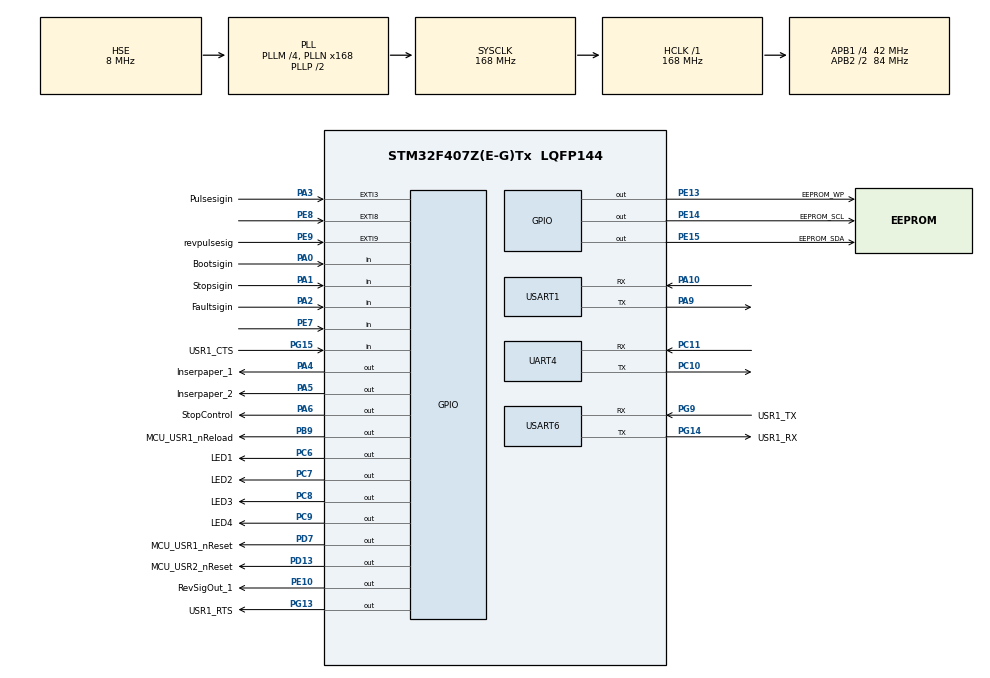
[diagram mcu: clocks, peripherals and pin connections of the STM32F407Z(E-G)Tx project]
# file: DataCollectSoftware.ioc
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Dma.Request0=USART6_TX
Dma.Request1=UART4_TX
Dma.Request2=UART4_RX
Dma.Request3=USART6_RX
Dma.Request4=USART1_RX
Dma.Request5=USART1_TX
Dma.UART4_RX.2.Direction=DMA_PERIPH_TO_MEMORY
Dma.UART4_RX.2.FIFOMode=DMA_FIFOMODE_DISABLE
Dma.UART4_RX.2.Instance=DMA1_Stream2
Dma.UART4_RX.2.MemDataAlignment=DMA_MDATAALIGN_BYTE
Dma.UART4_RX.2.MemInc=DMA_MINC_ENABLE
Dma.UART4_RX.2.Mode=DMA_NORMAL
Dma.UART4_RX.2.PeriphDataAlignment=DMA_PDATAALIGN_BYTE
Dma.UART4_RX.2.PeriphInc=DMA_PINC_DISABLE
Dma.UART4_RX.2.Priority=DMA_PRIORITY_LOW
Dma.UART4_TX.1.Direction=DMA_MEMORY_TO_PERIPH
Dma.UART4_TX.1.FIFOMode=DMA_FIFOMODE_DISABLE
Dma.UART4_TX.1.Instance=DMA1_Stream4
Dma.UART4_TX.1.MemDataAlignment=DMA_MDATAALIGN_BYTE
Dma.UART4_TX.1.MemInc=DMA_MINC_ENABLE
Dma.UART4_TX.1.Mode=DMA_NORMAL
Dma.UART4_TX.1.PeriphDataAlignment=DMA_PDATAALIGN_BYTE
Dma.UART4_TX.1.PeriphInc=DMA_PINC_DISABLE
Dma.UART4_TX.1.Priority=DMA_PRIORITY_LOW
Dma.USART1_RX.4.Direction=DMA_PERIPH_TO_MEMORY
Dma.USART1_RX.4.FIFOMode=DMA_FIFOMODE_DISABLE
Dma.USART1_RX.4.Instance=DMA2_Stream2
Dma.USART1_RX.4.MemDataAlignment=DMA_MDATAALIGN_BYTE
Dma.USART1_RX.4.MemInc=DMA_MINC_ENABLE
Dma.USART1_RX.4.Mode=DMA_NORMAL
Dma.USART1_RX.4.PeriphDataAlignment=DMA_PDATAALIGN_BYTE
Dma.USART1_RX.4.PeriphInc=DMA_PINC_DISABLE
Dma.USART1_RX.4.Priority=DMA_PRIORITY_LOW
Dma.USART1_TX.5.Direction=DMA_MEMORY_TO_PERIPH
Dma.USART1_TX.5.FIFOMode=DMA_FIFOMODE_DISABLE
Dma.USART1_TX.5.Instance=DMA2_Stream7
Dma.USART1_TX.5.MemDataAlignment=DMA_MDATAALIGN_BYTE
Dma.USART1_TX.5.MemInc=DMA_MINC_ENABLE
Dma.USART1_TX.5.Mode=DMA_NORMAL
Dma.USART1_TX.5.PeriphDataAlignment=DMA_PDATAALIGN_BYTE
Dma.USART1_TX.5.PeriphInc=DMA_PINC_DISABLE
Dma.USART1_TX.5.Priority=DMA_PRIORITY_LOW
Dma.USART6_RX.3.Direction=DMA_PERIPH_TO_MEMORY
Dma.USART6_RX.3.FIFOMode=DMA_FIFOMODE_DISABLE
Dma.USART6_RX.3.Instance=DMA2_Stream1
Dma.USART6_RX.3.MemDataAlignment=DMA_MDATAALIGN_BYTE
Dma.USART6_RX.3.MemInc=DMA_MINC_ENABLE
Dma.USART6_RX.3.Mode=DMA_NORMAL
Dma.USART6_RX.3.PeriphDataAlignment=DMA_PDATAALIGN_BYTE
Dma.USART6_RX.3.PeriphInc=DMA_PINC_DISABLE
Dma.USART6_RX.3.Priority=DMA_PRIORITY_LOW
Dma.USART6_TX.0.Direction=DMA_MEMORY_TO_PERIPH
Dma.USART6_TX.0.FIFOMode=DMA_FIFOMODE_DISABLE
Dma.USART6_TX.0.Instance=DMA2_Stream6
Dma.USART6_TX.0.MemDataAlignment=DMA_MDATAALIGN_BYTE
Dma.USART6_TX.0.MemInc=DMA_MINC_ENABLE
Dma.USART6_TX.0.Mode=DMA_NORMAL
Dma.USART6_TX.0.PeriphDataAlignment=DMA_PDATAALIGN_BYTE
Dma.USART6_TX.0.PeriphInc=DMA_PINC_DISABLE
Dma.USART6_TX.0.Priority=DMA_PRIORITY_LOW
FREERTOS.Mutexes01=CommitMutex,Dynamic,NULL
FREERTOS.Tasks01=Collect_Task,0,500,StartCollectTask,Default,NULL,Dynamic,NULL,NULL;Config_Task,-3,500,StartConfigTask,Default,NULL,Dynamic,NULL,NULL;OutControl_Task,-3,128,StartOutControlTask,Default,NULL,Dynamic,NULL,NULL
Mcu.Family=STM32F4
Mcu.Name=STM32F407Z(E-G)Tx
Mcu.Package=LQFP144
NVIC.DMA1_Stream2_IRQn=true\:5\:0\:false\:false\:true\:true\:false\:true
NVIC.DMA1_Stream4_IRQn=true\:5\:0\:false\:false\:true\:true\:false\:true
NVIC.DMA2_Stream1_IRQn=true\:5\:0\:false\:false\:true\:true\:false\:true
NVIC.DMA2_Stream2_IRQn=true\:5\:0\:false\:false\:true\:true\:false\:true
NVIC.DMA2_Stream6_IRQn=true\:5\:0\:false\:false\:true\:true\:true\:false
NVIC.DMA2_Stream7_IRQn=true\:5\:0\:false\:false\:true\:true\:false\:true
NVIC.EXTI3_IRQn=true\:5\:0\:true\:false\:true\:true\:true\:true
NVIC.EXTI9_5_IRQn=true\:5\:0\:false\:false\:true\:true\:true\:true
NVIC.PriorityGroup=NVIC_PRIORITYGROUP_4
NVIC.TIM2_IRQn=true\:5\:0\:false\:false\:true\:true\:true\:true
NVIC.TIM3_IRQn=true\:5\:0\:false\:false\:true\:true\:true\:true
NVIC.TIM4_IRQn=true\:5\:0\:false\:false\:true\:true\:true\:true
NVIC.TIM8_TRG_COM_TIM14_IRQn=true\:0\:0\:false\:false\:true\:false\:false\:false
NVIC.TimeBase=TIM8_TRG_COM_TIM14_IRQn
NVIC.TimeBaseIP=TIM14
NVIC.UART4_IRQn=true\:5\:0\:false\:false\:true\:true\:true\:true
NVIC.USART1_IRQn=true\:5\:0\:false\:false\:true\:true\:true\:true
NVIC.USART6_IRQn=true\:5\:0\:false\:false\:true\:true\:true\:true
PA0-WKUP.GPIO_Label=Bootsigin
PA0-WKUP.GPIO_Mode=GPIO_MODE_INPUT
PA0-WKUP.GPIO_PuPd=GPIO_NOPULL
PA0-WKUP.Signal=GPIO_Input
PA1.GPIO_Label=Stopsigin
PA1.GPIO_Mode=GPIO_MODE_INPUT
PA1.GPIO_PuPd=GPIO_NOPULL
PA1.Signal=GPIO_Input
PA10.Mode=Asynchronous
PA10.Signal=USART1_RX
PA13.Mode=JTAG_5_pins
PA13.Signal=SYS_JTMS-SWDIO
PA14.Mode=JTAG_5_pins
PA14.Signal=SYS_JTCK-SWCLK
PA15.Mode=JTAG_5_pins
PA15.Signal=SYS_JTDI
PA2.GPIO_Label=Faultsigin
PA2.GPIO_Mode=GPIO_MODE_INPUT
PA2.GPIO_PuPd=GPIO_NOPULL
PA2.Signal=GPIO_Input
PA3.GPIO_Label=Pulsesigin
PA3.GPIO_ModeDefaultEXTI=GPIO_MODE_IT_RISING_FALLING
PA3.Signal=GPXTI3
PA4.GPIO_Label=Inserpaper_1
PA4.GPIO_ModeDefaultOutputPP=GPIO_MODE_OUTPUT_PP
PA4.GPIO_PuPd=GPIO_PULLUP
PA4.GPIO_Speed=GPIO_SPEED_FREQ_LOW
PA4.PinState=GPIO_PIN_RESET
PA4.Signal=GPIO_Output
PA5.GPIO_Label=Inserpaper_2
PA5.GPIO_ModeDefaultOutputPP=GPIO_MODE_OUTPUT_PP
PA5.GPIO_PuPd=GPIO_PULLUP
PA5.GPIO_Speed=GPIO_SPEED_FREQ_LOW
PA5.PinState=GPIO_PIN_RESET
PA5.Signal=GPIO_Output
PA6.GPIO_Label=StopControl
PA6.GPIO_ModeDefaultOutputPP=GPIO_MODE_OUTPUT_PP
PA6.GPIO_PuPd=GPIO_PULLUP
PA6.GPIO_Speed=GPIO_SPEED_FREQ_LOW
PA6.PinState=GPIO_PIN_RESET
PA6.Signal=GPIO_Output
PA9.Mode=Asynchronous
PA9.Signal=USART1_TX
PB3.Mode=JTAG_5_pins
PB3.Signal=SYS_JTDO-SWO
PB4.Mode=JTAG_5_pins
PB4.Signal=SYS_JTRST
PB9.GPIO_Label=MCU_USR1_nReload
PB9.GPIO_ModeDefaultOutputPP=GPIO_MODE_OUTPUT_PP
PB9.GPIO_PuPd=GPIO_PULLUP
PB9.GPIO_Speed=GPIO_SPEED_FREQ_LOW
PB9.PinState=GPIO_PIN_SET
PB9.Signal=GPIO_Output
PC10.Mode=Asynchronous
PC10.Signal=UART4_TX
PC11.Mode=Asynchronous
PC11.Signal=UART4_RX
PC14-OSC32_IN.Mode=LSE-External-Oscillator
PC14-OSC32_IN.Signal=RCC_OSC32_IN
PC15-OSC32_OUT.Mode=LSE-External-Oscillator
PC15-OSC32_OUT.Signal=RCC_OSC32_OUT
PC6.GPIO_Label=LED1
PC6.GPIO_PuPd=GPIO_PULLUP
PC6.Signal=GPIO_Output
PC7.GPIO_Label=LED2
PC7.Signal=GPIO_Output
PC8.GPIO_Label=LED3
PC8.Signal=GPIO_Output
PC9.GPIO_Label=LED4
PC9.Signal=GPIO_Output
PD13.GPIO_Label=MCU_USR2_nReset
PD13.GPIO_PuPd=GPIO_PULLUP
PD13.Signal=GPIO_Output
PD7.GPIO_Label=MCU_USR1_nReset
PD7.GPIO_ModeDefaultOutputPP=GPIO_MODE_OUTPUT_PP
PD7.GPIO_PuPd=GPIO_PULLUP
PD7.GPIO_Speed=GPIO_SPEED_FREQ_LOW
PD7.PinState=GPIO_PIN_SET
PD7.Signal=GPIO_Output
PE10.GPIO_Label=RevSigOut_1
PE10.GPIO_ModeDefaultOutputPP=GPIO_MODE_OUTPUT_PP
PE10.GPIO_PuPd=GPIO_PULLUP
PE10.GPIO_Speed=GPIO_SPEED_FREQ_LOW
PE10.PinState=GPIO_PIN_RESET
PE10.Signal=GPIO_Output
PE13.GPIO_Label=EEPROM_WP
PE13.GPIO_ModeDefaultOutputPP=GPIO_MODE_OUTPUT_PP
PE13.GPIO_PuPd=GPIO_PULLUP
PE13.GPIO_Speed=GPIO_SPEED_FREQ_LOW
PE13.PinState=GPIO_PIN_RESET
PE13.Signal=GPIO_Output
PE14.GPIO_Label=EEPROM_SCL
PE14.GPIO_ModeDefaultOutputPP=GPIO_MODE_OUTPUT_PP
PE14.GPIO_PuPd=GPIO_PULLUP
PE14.GPIO_Speed=GPIO_SPEED_FREQ_HIGH
PE14.Signal=GPIO_Output
PE15.GPIO_Label=EEPROM_SDA
PE15.GPIO_ModeDefaultOutputPP=GPIO_MODE_OUTPUT_OD
PE15.GPIO_PuPd=GPIO_PULLUP
PE15.GPIO_Speed=GPIO_SPEED_FREQ_HIGH
PE15.Signal=GPIO_Output
PE7.Signal=GPIO_Input
PE8.GPIO_ModeDefaultEXTI=GPIO_MODE_IT_RISING_FALLING
PE8.Signal=GPXTI8
PE9.GPIO_Label=revpulsesig
PE9.GPIO_ModeDefaultEXTI=GPIO_MODE_IT_RISING_FALLING
PE9.Signal=GPXTI9
PG13.GPIO_Label=USR1_RTS
PG13.GPIO_ModeDefaultOutputPP=GPIO_MODE_OUTPUT_PP
PG13.GPIO_PuPd=GPIO_PULLUP
PG13.GPIO_Speed=GPIO_SPEED_FREQ_LOW
PG13.PinState=GPIO_PIN_RESET
PG13.Signal=GPIO_Output
PG14.GPIO_Label=USR1_RX
PG14.Mode=Asynchronous
PG14.Signal=USART6_TX
PG15.GPIO_Label=USR1_CTS
PG15.GPIO_Mode=GPIO_MODE_INPUT
PG15.GPIO_PuPd=GPIO_PULLUP
PG15.Signal=GPIO_Input
PG9.GPIO_Label=USR1_TX
PG9.Mode=Asynchronous
PG9.Signal=USART6_RX
PH0-OSC_IN.Mode=HSE-External-Oscillator
PH0-OSC_IN.Signal=RCC_OSC_IN
PH1-OSC_OUT.Mode=HSE-External-Oscillator
PH1-OSC_OUT.Signal=RCC_OSC_OUT
ProjectManager.HeapSize=0xc00
ProjectManager.StackSize=0x400
ProjectManager.TargetToolchain=MDK-ARM V5
RCC.48MHZClocksFreq_Value=84000000
RCC.AHBFreq_Value=168000000
RCC.APB1CLKDivider=RCC_HCLK_DIV4
RCC.APB1Freq_Value=42000000
RCC.APB1TimFreq_Value=84000000
RCC.APB2CLKDivider=RCC_HCLK_DIV2
RCC.APB2Freq_Value=84000000
RCC.APB2TimFreq_Value=168000000
RCC.CortexFreq_Value=168000000
RCC.HCLKFreq_Value=168000000
RCC.HSE_VALUE=8000000
RCC.HSI_VALUE=16000000
RCC.PLLM=4
RCC.PLLN=168
RCC.PLLSourceVirtual=RCC_PLLSOURCE_HSE
RCC.RCC_RTC_Clock_SourceVirtual=RCC_RTCCLKSOURCE_LSE
RCC.RCC_RTC_Clock_Source_FROM_HSE=RCC_RTCCLKSOURCE_HSE_DIV8
RCC.SYSCLKFreq_VALUE=168000000
RCC.SYSCLKSource=RCC_SYSCLKSOURCE_PLLCLK
RCC.VCOOutputFreq_Value=336000000
TIM2.AutoReloadPreload=TIM_AUTORELOAD_PRELOAD_ENABLE
TIM2.Period=1000
TIM2.Prescaler=83
TIM3.AutoReloadPreload=TIM_AUTORELOAD_PRELOAD_ENABLE
TIM3.Period=9999
TIM3.Prescaler=8399
TIM4.AutoReloadPreload=TIM_AUTORELOAD_PRELOAD_ENABLE
TIM4.Period=1000
TIM4.Prescaler=83
UART4.VirtualMode=Asynchronous
USART1.VirtualMode=VM_ASYNC
USART6.VirtualMode=VM_ASYNC
VP_FREERTOS_VS_CMSIS_V1.Mode=CMSIS_V1
VP_RTC_VS_RTC_Activate.Mode=RTC_Enabled
VP_SYS_VS_tim14.Mode=TIM14
VP_TIM2_VS_ClockSourceINT.Mode=Internal
VP_TIM3_VS_ClockSourceINT.Mode=Internal
VP_TIM4_VS_ClockSourceINT.Mode=Internal
board=custom

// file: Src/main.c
/* USER CODE BEGIN Header */
/**
  ******************************************************************************
  * @file           : main.c
  * @brief          : Main program body
  ******************************************************************************
  * This notice applies to any and all portions of this file
  * that are not between comment pairs USER CODE BEGIN and
  * USER CODE END. Other portions of this file, whether
  * inserted by the user or by software development tools
  * are owned by their respective copyright owners.
  *
  * Copyright (c) 2019 STMicroelectronics International N.V.
  * All rights reserved.
  *
  * Redistribution and use in source and binary forms, with or without
  * modification, are permitted, provided that the following conditions are met:
  *
  * 1. Redistribution of source code must retain the above copyright notice,
  *    this list of conditions and the following disclaimer.
  * 2. Redistributions in binary form must reproduce the above copyright notice,
  *    this list of conditions and the following disclaimer in the documentation
  *    and/or other materials provided with the distribution.
  * 3. Neither the name of STMicroelectronics nor the names of other
  *    contributors to this software may be used to endorse or promote products
  *    derived from this software without specific written permission.
  * 4. This software, including modifications and/or derivative works of this
  *    software, must execute solely and exclusively on microcontroller or
  *    microprocessor devices manufactured by or for STMicroelectronics.
  * 5. Redistribution and use of this software other than as permitted under
  *    this license is void and will automatically terminate your rights under
  *    this license.
  *
  * THIS SOFTWARE IS PROVIDED BY STMICROELECTRONICS AND CONTRIBUTORS "AS IS"
  * AND ANY EXPRESS, IMPLIED OR STATUTORY WARRANTIES, INCLUDING, BUT NOT
  * LIMITED TO, THE IMPLIED WARRANTIES OF MERCHANTABILITY, FITNESS FOR A
  * PARTICULAR PURPOSE AND NON-INFRINGEMENT OF THIRD PARTY INTELLECTUAL PROPERTY
  * RIGHTS ARE DISCLAIMED TO THE FULLEST EXTENT PERMITTED BY LAW. IN NO EVENT
  * SHALL STMICROELECTRONICS OR CONTRIBUTORS BE LIABLE FOR ANY DIRECT, INDIRECT,
  * INCIDENTAL, SPECIAL, EXEMPLARY, OR CONSEQUENTIAL DAMAGES (INCLUDING, BUT NOT
  * LIMITED TO, PROCUREMENT OF SUBSTITUTE GOODS OR SERVICES; LOSS OF USE, DATA,
  * OR PROFITS; OR BUSINESS INTERRUPTION) HOWEVER CAUSED AND ON ANY THEORY OF
  * LIABILITY, WHETHER IN CONTRACT, STRICT LIABILITY, OR TORT (INCLUDING
  * NEGLIGENCE OR OTHERWISE) ARISING IN ANY WAY OUT OF THE USE OF THIS SOFTWARE,
  * EVEN IF ADVISED OF THE POSSIBILITY OF SUCH DAMAGE.
  *
  ******************************************************************************
  */
/* USER CODE END Header */

#include "main.h"
#include "cmsis_os.h"
#include <stdio.h>

/* USER CODE BEGIN Includes */
#include "system_config.h"
#include "maincounter.h"
#include "qulitycounter.h"
#include "diechangecounter.h"

//#include "waveformcapture.h"

/* USER CODE END Includes */

/* USER CODE BEGIN PTD */
#define   APPLICATION_ADDR  0x08010000
/* USER CODE END PTD */

RTC_HandleTypeDef hrtc;

TIM_HandleTypeDef htim2;
TIM_HandleTypeDef htim3;
TIM_HandleTypeDef htim4;

UART_HandleTypeDef huart4;
UART_HandleTypeDef huart1;
UART_HandleTypeDef huart6;
DMA_HandleTypeDef hdma_uart4_tx;
DMA_HandleTypeDef hdma_uart4_rx;
DMA_HandleTypeDef hdma_usart1_rx;
DMA_HandleTypeDef hdma_usart1_tx;
DMA_HandleTypeDef hdma_usart6_tx;
DMA_HandleTypeDef hdma_usart6_rx;

osThreadId Collect_TaskHandle;
osThreadId Config_TaskHandle;
osThreadId OutControl_TaskHandle;
osThreadId Collect_TaskHandle_new;
osMutexId CommitMutexHandle;
/* USER CODE BEGIN PV */
SysCfg g_sys_cfg;
SysSts g_sys_sts;
/* USER CODE END PV */

void SystemClock_Config(void);
static void MX_GPIO_Init(void);
static void MX_DMA_Init(void);
static void MX_UART4_Init(void);
static void MX_USART6_UART_Init(void);
static void MX_RTC_Init(void);
static void MX_TIM2_Init(void);
static void MX_TIM3_Init(void);
static void MX_TIM4_Init(void);
static void MX_USART1_UART_Init(void);
void StartCollectTask(void const * argument);
void StartConfigTask(void const * argument);
void StartOutControlTask(void const * argument);
void StartCollectTask_new(void const * argument);

/* USER CODE BEGIN 0 */
int fputc(int ch,FILE *f)
{
	uint8_t u8ch = (uint8_t)ch;

    while(HAL_UART_Transmit_DMA(&huart4, &u8ch, 1)!= HAL_OK);

    return u8ch;
}

/* USER CODE END 0 */

int main(void)
{
  /* USER CODE BEGIN 1 */
  SCB->VTOR =  APPLICATION_ADDR;
  /* USER CODE END 1 */
  __set_PRIMASK(0);
  __set_FAULTMASK(0);

  /* MCU Configuration--------------------------------------------------------*/

  /* Reset of all peripherals, Initializes the Flash interface and the Systick. */
  HAL_Init();

  /* Configure the system clock */
  SystemClock_Config();

  /* Initialize all configured peripherals */
  MX_GPIO_Init();
  MX_DMA_Init();
  MX_UART4_Init();
  MX_USART6_UART_Init();
  MX_RTC_Init();
  MX_TIM2_Init();
  MX_TIM3_Init();
  MX_TIM4_Init();
  MX_USART1_UART_Init();
  /* USER CODE BEGIN 2 */
  system_init();
  /* USER CODE END 2 */

  /* Create the mutex(es) */
  /* definition and creation of CommitMutex */
  osMutexDef(CommitMutex);
  CommitMutexHandle = osMutexCreate(osMutex(CommitMutex));
//  CommitBladeData_Upload();

  /* Create the thread(s) */
  /* definition and creation of Collect_Task */
  osThreadDef(Collect_Task, StartCollectTask, osPriorityNormal, 0, 500);
  Collect_TaskHandle = osThreadCreate(osThread(Collect_Task), NULL);

  /* definition and creation of Config_Task */
  osThreadDef(Config_Task, StartConfigTask, osPriorityIdle, 0, 500);
  Config_TaskHandle = osThreadCreate(osThread(Config_Task), NULL);

  /* definition and creation of OutControl_Task */
  osThreadDef(OutControl_Task, StartOutControlTask, osPriorityIdle, 0, 128);
  OutControl_TaskHandle = osThreadCreate(osThread(OutControl_Task), NULL);

  /* USER CODE BEGIN RTOS_THREADS */
  osThreadDef(Collect_new_Task, StartCollectTask_new, osPriorityAboveNormal, 0, 500);
  Collect_TaskHandle_new = osThreadCreate(osThread(Collect_new_Task), NULL);

  /* add threads, ... */
  /* USER CODE END RTOS_THREADS */

  /* Start scheduler */
  osKernelStart();

  /* We should never get here as control is now taken by the scheduler */

  /* Infinite loop */
  while (1)
  {

  }
}

void SystemClock_Config(void)
{
  RCC_OscInitTypeDef RCC_OscInitStruct = {0};
  RCC_ClkInitTypeDef RCC_ClkInitStruct = {0};
  RCC_PeriphCLKInitTypeDef PeriphClkInitStruct = {0};

  /** Configure the main internal regulator output voltage
  */
  __HAL_RCC_PWR_CLK_ENABLE();
  __HAL_PWR_VOLTAGESCALING_CONFIG(PWR_REGULATOR_VOLTAGE_SCALE1);
  /** Initializes the CPU, AHB and APB busses clocks
  */
  RCC_OscInitStruct.OscillatorType = RCC_OSCILLATORTYPE_HSE|RCC_OSCILLATORTYPE_LSE;
  RCC_OscInitStruct.HSEState = RCC_HSE_ON;
  RCC_OscInitStruct.LSEState = RCC_LSE_ON;
  RCC_OscInitStruct.PLL.PLLState = RCC_PLL_ON;
  RCC_OscInitStruct.PLL.PLLSource = RCC_PLLSOURCE_HSE;
  RCC_OscInitStruct.PLL.PLLM = 4;
  RCC_OscInitStruct.PLL.PLLN = 168;
  RCC_OscInitStruct.PLL.PLLP = RCC_PLLP_DIV2;
  RCC_OscInitStruct.PLL.PLLQ = 4;
  if (HAL_RCC_OscConfig(&RCC_OscInitStruct) != HAL_OK)
  {
    Error_Handler();
  }
  /** Initializes the CPU, AHB and APB busses clocks
  */
  RCC_ClkInitStruct.ClockType = RCC_CLOCKTYPE_HCLK|RCC_CLOCKTYPE_SYSCLK
                              |RCC_CLOCKTYPE_PCLK1|RCC_CLOCKTYPE_PCLK2;
  RCC_ClkInitStruct.SYSCLKSource = RCC_SYSCLKSOURCE_PLLCLK;
  RCC_ClkInitStruct.AHBCLKDivider = RCC_SYSCLK_DIV1;
  RCC_ClkInitStruct.APB1CLKDivider = RCC_HCLK_DIV4;
  RCC_ClkInitStruct.APB2CLKDivider = RCC_HCLK_DIV2;

  if (HAL_RCC_ClockConfig(&RCC_ClkInitStruct, FLASH_LATENCY_5) != HAL_OK)
  {
    Error_Handler();
  }
  PeriphClkInitStruct.PeriphClockSelection = RCC_PERIPHCLK_RTC;
  PeriphClkInitStruct.RTCClockSelection = RCC_RTCCLKSOURCE_LSE;
  if (HAL_RCCEx_PeriphCLKConfig(&PeriphClkInitStruct) != HAL_OK)
  {
    Error_Handler();
  }
}

static void MX_RTC_Init(void)
{

  /** Initialize RTC Only
  */
  hrtc.Instance = RTC;
  hrtc.Init.HourFormat = RTC_HOURFORMAT_24;
  hrtc.Init.AsynchPrediv = 127;
  hrtc.Init.SynchPrediv = 255;
  hrtc.Init.OutPut = RTC_OUTPUT_DISABLE;
  hrtc.Init.OutPutPolarity = RTC_OUTPUT_POLARITY_HIGH;
  hrtc.Init.OutPutType = RTC_OUTPUT_TYPE_OPENDRAIN;
  if (HAL_RTC_Init(&hrtc) != HAL_OK)
  {
    Error_Handler();
  }

}

static void MX_TIM2_Init(void)
{

  TIM_ClockConfigTypeDef sClockSourceConfig = {0};
  TIM_MasterConfigTypeDef sMasterConfig = {0};

  htim2.Instance = TIM2;
  htim2.Init.Prescaler = 83;
  htim2.Init.CounterMode = TIM_COUNTERMODE_UP;
  htim2.Init.Period = 1000;
  htim2.Init.ClockDivision = TIM_CLOCKDIVISION_DIV1;
  htim2.Init.AutoReloadPreload = TIM_AUTORELOAD_PRELOAD_ENABLE;
  if (HAL_TIM_Base_Init(&htim2) != HAL_OK)
  {
    Error_Handler();
  }
  sClockSourceConfig.ClockSource = TIM_CLOCKSOURCE_INTERNAL;
  if (HAL_TIM_ConfigClockSource(&htim2, &sClockSourceConfig) != HAL_OK)
  {
    Error_Handler();
  }
  sMasterConfig.MasterOutputTrigger = TIM_TRGO_RESET;
  sMasterConfig.MasterSlaveMode = TIM_MASTERSLAVEMODE_DISABLE;
  if (HAL_TIMEx_MasterConfigSynchronization(&htim2, &sMasterConfig) != HAL_OK)
  {
    Error_Handler();
  }
  /* USER CODE BEGIN TIM2_Init 2 */
   HAL_TIM_Base_Start_IT(&htim2);
  /* USER CODE END TIM2_Init 2 */

}

static void MX_TIM3_Init(void)
{

  TIM_ClockConfigTypeDef sClockSourceConfig = {0};
  TIM_MasterConfigTypeDef sMasterConfig = {0};

  htim3.Instance = TIM3;
  htim3.Init.Prescaler = 8399;
  htim3.Init.CounterMode = TIM_COUNTERMODE_UP;
  htim3.Init.Period = 9999;
  htim3.Init.ClockDivision = TIM_CLOCKDIVISION_DIV1;
  htim3.Init.AutoReloadPreload = TIM_AUTORELOAD_PRELOAD_ENABLE;
  if (HAL_TIM_Base_Init(&htim3) != HAL_OK)
  {
    Error_Handler();
  }
  sClockSourceConfig.ClockSource = TIM_CLOCKSOURCE_INTERNAL;
  if (HAL_TIM_ConfigClockSource(&htim3, &sClockSourceConfig) != HAL_OK)
  {
    Error_Handler();
  }
  sMasterConfig.MasterOutputTrigger = TIM_TRGO_RESET;
  sMasterConfig.MasterSlaveMode = TIM_MASTERSLAVEMODE_DISABLE;
  if (HAL_TIMEx_MasterConfigSynchronization(&htim3, &sMasterConfig) != HAL_OK)
  {
    Error_Handler();
  }
  /* USER CODE BEGIN TIM3_Init 2 */
   HAL_TIM_Base_Start_IT(&htim3);
  /* USER CODE END TIM3_Init 2 */

}

static void MX_TIM4_Init(void)
{

  TIM_ClockConfigTypeDef sClockSourceConfig = {0};
  TIM_MasterConfigTypeDef sMasterConfig = {0};

  htim4.Instance = TIM4;
  htim4.Init.Prescaler = 83;
  htim4.Init.CounterMode = TIM_COUNTERMODE_UP;
  htim4.Init.Period = 1000;
  htim4.Init.ClockDivision = TIM_CLOCKDIVISION_DIV1;
  htim4.Init.AutoReloadPreload = TIM_AUTORELOAD_PRELOAD_ENABLE;
  if (HAL_TIM_Base_Init(&htim4) != HAL_OK)
  {
    Error_Handler();
  }
  sClockSourceConfig.ClockSource = TIM_CLOCKSOURCE_INTERNAL;
  if (HAL_TIM_ConfigClockSource(&htim4, &sClockSourceConfig) != HAL_OK)
  {
    Error_Handler();
  }
  sMasterConfig.MasterOutputTrigger = TIM_TRGO_RESET;
  sMasterConfig.MasterSlaveMode = TIM_MASTERSLAVEMODE_DISABLE;
  if (HAL_TIMEx_MasterConfigSynchronization(&htim4, &sMasterConfig) != HAL_OK)
  {
    Error_Handler();
  }
  /* USER CODE BEGIN TIM4_Init 2 */
   HAL_TIM_Base_Start_IT(&htim4);
  /* USER CODE END TIM4_Init 2 */

}

static void MX_UART4_Init(void)
{

  huart4.Instance = UART4;
  huart4.Init.BaudRate = 115200;
  huart4.Init.WordLength = UART_WORDLENGTH_8B;
  huart4.Init.StopBits = UART_STOPBITS_1;
  huart4.Init.Parity = UART_PARITY_NONE;
  huart4.Init.Mode = UART_MODE_TX_RX;
  huart4.Init.HwFlowCtl = UART_HWCONTROL_NONE;
  huart4.Init.OverSampling = UART_OVERSAMPLING_16;
  if (HAL_UART_Init(&huart4) != HAL_OK)
  {
    Error_Handler();
  }

}

static void MX_USART1_UART_Init(void)
{

  huart1.Instance = USART1;
  huart1.Init.BaudRate = 115200;
  huart1.Init.WordLength = UART_WORDLENGTH_8B;
  huart1.Init.StopBits = UART_STOPBITS_1;
  huart1.Init.Parity = UART_PARITY_NONE;
  huart1.Init.Mode = UART_MODE_TX_RX;
  huart1.Init.HwFlowCtl = UART_HWCONTROL_NONE;
  huart1.Init.OverSampling = UART_OVERSAMPLING_16;
  if (HAL_UART_Init(&huart1) != HAL_OK)
  {
    Error_Handler();
  }
  /* USER CODE BEGIN USART1_Init 2 */
  HAL_UART_Receive_DMA(&huart1,g_sys_sts.uart_frm.rxbuf,1);
  /* USER CODE END USART1_Init 2 */

}
static void MX_USART6_UART_Init(void)
{

  huart6.Instance = USART6;
  huart6.Init.BaudRate = 115200;
  huart6.Init.WordLength = UART_WORDLENGTH_8B;
  huart6.Init.StopBits = UART_STOPBITS_1;
  huart6.Init.Parity = UART_PARITY_NONE;
  huart6.Init.Mode = UART_MODE_TX_RX;
  huart6.Init.HwFlowCtl = UART_HWCONTROL_NONE;
  huart6.Init.OverSampling = UART_OVERSAMPLING_16;
  if (HAL_UART_Init(&huart6) != HAL_OK)
  {
    Error_Handler();
  }
  /* USER CODE BEGIN USART6_Init 2 */
	HAL_UART_Receive_DMA(&huart6,&g_sys_sts.wifi_cfg_mgr.RxUartData,1);
  /* USER CODE END USART6_Init 2 */

}

static void MX_DMA_Init(void)
{

  /* DMA controller clock enable */
  __HAL_RCC_DMA2_CLK_ENABLE();
  __HAL_RCC_DMA1_CLK_ENABLE();

  /* DMA interrupt init */
  /* DMA1_Stream2_IRQn interrupt configuration */
  HAL_NVIC_SetPriority(DMA1_Stream2_IRQn, 5, 0);
  HAL_NVIC_EnableIRQ(DMA1_Stream2_IRQn);
  /* DMA1_Stream4_IRQn interrupt configuration */
  HAL_NVIC_SetPriority(DMA1_Stream4_IRQn, 5, 0);
  HAL_NVIC_EnableIRQ(DMA1_Stream4_IRQn);
  /* DMA2_Stream1_IRQn interrupt configuration */
  HAL_NVIC_SetPriority(DMA2_Stream1_IRQn, 5, 0);
  HAL_NVIC_EnableIRQ(DMA2_Stream1_IRQn);
  /* DMA2_Stream2_IRQn interrupt configuration */
  HAL_NVIC_SetPriority(DMA2_Stream2_IRQn, 5, 0);
  HAL_NVIC_EnableIRQ(DMA2_Stream2_IRQn);
  /* DMA2_Stream6_IRQn interrupt configuration */
  HAL_NVIC_SetPriority(DMA2_Stream6_IRQn, 5, 0);
  HAL_NVIC_EnableIRQ(DMA2_Stream6_IRQn);
  /* DMA2_Stream7_IRQn interrupt configuration */
  HAL_NVIC_SetPriority(DMA2_Stream7_IRQn, 5, 0);
  HAL_NVIC_EnableIRQ(DMA2_Stream7_IRQn);

}

static void MX_GPIO_Init(void)
{
  GPIO_InitTypeDef GPIO_InitStruct = {0};

  /* GPIO Ports Clock Enable */
  __HAL_RCC_GPIOC_CLK_ENABLE();
  __HAL_RCC_GPIOH_CLK_ENABLE();
  __HAL_RCC_GPIOA_CLK_ENABLE();
  __HAL_RCC_GPIOE_CLK_ENABLE();
  __HAL_RCC_GPIOD_CLK_ENABLE();
  __HAL_RCC_GPIOG_CLK_ENABLE();
  __HAL_RCC_GPIOB_CLK_ENABLE();

  /*Configure GPIO pin Output Level */
  HAL_GPIO_WritePin(GPIOA, Inserpaper_1_Pin|Inserpaper_2_Pin|StopControl_Pin, GPIO_PIN_RESET);

  /*Configure GPIO pin Output Level */
  HAL_GPIO_WritePin(GPIOE, RevSigOut_1_Pin|EEPROM_WP_Pin|EEPROM_SCL_Pin|EEPROM_SDA_Pin, GPIO_PIN_RESET);

  /*Configure GPIO pin Output Level */
  HAL_GPIO_WritePin(MCU_USR2_nReset_GPIO_Port, MCU_USR2_nReset_Pin, GPIO_PIN_RESET);

  /*Configure GPIO pin Output Level */
  HAL_GPIO_WritePin(GPIOC, LED1_Pin|LED2_Pin|LED3_Pin|LED4_Pin, GPIO_PIN_RESET);

  /*Configure GPIO pin Output Level */
  HAL_GPIO_WritePin(MCU_USR1_nReset_GPIO_Port, MCU_USR1_nReset_Pin, GPIO_PIN_SET);

  /*Configure GPIO pin Output Level */
  HAL_GPIO_WritePin(USR1_RTS_GPIO_Port, USR1_RTS_Pin, GPIO_PIN_RESET);

  /*Configure GPIO pin Output Level */
  HAL_GPIO_WritePin(MCU_USR1_nReload_GPIO_Port, MCU_USR1_nReload_Pin, GPIO_PIN_SET);

  /*Configure GPIO pins : Bootsigin_Pin Stopsigin_Pin Faultsigin_Pin */
  GPIO_InitStruct.Pin = Bootsigin_Pin|Stopsigin_Pin|Faultsigin_Pin;
  GPIO_InitStruct.Mode = GPIO_MODE_INPUT;
  GPIO_InitStruct.Pull = GPIO_NOPULL;
  HAL_GPIO_Init(GPIOA, &GPIO_InitStruct);

  /*Configure GPIO pin : Pulsesigin_Pin */
//  GPIO_InitStruct.Pin = Pulsesigin_Pin;
//  GPIO_InitStruct.Mode = GPIO_MODE_IT_RISING_FALLING;
//  GPIO_InitStruct.Pull = GPIO_NOPULL;
//  HAL_GPIO_Init(Pulsesigin_GPIO_Port, &GPIO_InitStruct);
  GPIO_InitStruct.Pin  = Pulsesigin_Pin;
  GPIO_InitStruct.Mode = GPIO_MODE_IT_RISING;
  GPIO_InitStruct.Pull = GPIO_NOPULL;
  GPIO_InitStruct.Speed = GPIO_SPEED_FREQ_VERY_HIGH;
  HAL_GPIO_Init(Pulsesigin_GPIO_Port, &GPIO_InitStruct);

  /*Configure GPIO pins : Inserpaper_1_Pin Inserpaper_2_Pin StopControl_Pin */
  GPIO_InitStruct.Pin = Inserpaper_1_Pin|Inserpaper_2_Pin|StopControl_Pin;
  GPIO_InitStruct.Mode = GPIO_MODE_OUTPUT_PP;
  GPIO_InitStruct.Pull = GPIO_PULLUP;
  GPIO_InitStruct.Speed = GPIO_SPEED_FREQ_LOW;
  HAL_GPIO_Init(GPIOA, &GPIO_InitStruct);

  /*Configure GPIO pin : PE7 */
//  GPIO_InitStruct.Pin = GPIO_PIN_7;
//  GPIO_InitStruct.Mode = GPIO_MODE_INPUT;
//  GPIO_InitStruct.Pull = GPIO_NOPULL;
//  HAL_GPIO_Init(GPIOE, &GPIO_InitStruct);

  /* 2020年04月15日 新增  重新设计计数方案 纸光电 外部中断模式 */
  GPIO_InitStruct.Pin 	  = Reservedpulse_Pin;
  GPIO_InitStruct.Mode	  = GPIO_MODE_IT_RISING_FALLING;
  GPIO_InitStruct.Pull	  = GPIO_NOPULL;
  GPIO_InitStruct.Speed	  = GPIO_SPEED_FREQ_VERY_HIGH;
  HAL_GPIO_Init(Reservedpulse_GPIO_Port, &GPIO_InitStruct);
  /* 2020年04月15日 新增  重新设计计数方案 纸光电 			  外部中断模式 */

  /* 2020年04月30日 新增质检计数 		 外部中断模式 */
  GPIO_InitStruct.Pin 	  = GPIO_PIN_8;
  GPIO_InitStruct.Mode	  = GPIO_MODE_IT_RISING;
  GPIO_InitStruct.Pull	  = GPIO_NOPULL;
  GPIO_InitStruct.Speed	  = GPIO_SPEED_FREQ_VERY_HIGH;
  HAL_GPIO_Init(GPIOE, &GPIO_InitStruct);
  /* 2020年04月30日 新增质检计数 		 外部中断模式 */

  /* 2020年04月30日 换模计数		   外部中断模式 */
  GPIO_InitStruct.Pin 	  = GPIO_PIN_9;
  GPIO_InitStruct.Mode	  = GPIO_MODE_IT_RISING;
  GPIO_InitStruct.Pull	  = GPIO_NOPULL;
  GPIO_InitStruct.Speed	  = GPIO_SPEED_FREQ_VERY_HIGH;
  HAL_GPIO_Init(GPIOE, &GPIO_InitStruct);
  /* 2020年04月30日 换模计数		   外部中断模式 */

//  /*Configure GPIO pins : PE8 revpulsesig_Pin */
//  GPIO_InitStruct.Pin = GPIO_PIN_8|revpulsesig_Pin;
//  GPIO_InitStruct.Mode = GPIO_MODE_IT_RISING_FALLING;
//  GPIO_InitStruct.Pull = GPIO_NOPULL;
//  HAL_GPIO_Init(GPIOE, &GPIO_InitStruct);

  /*Configure GPIO pins : RevSigOut_1_Pin EEPROM_WP_Pin */
  GPIO_InitStruct.Pin = RevSigOut_1_Pin|EEPROM_WP_Pin;
  GPIO_InitStruct.Mode = GPIO_MODE_OUTPUT_PP;
  GPIO_InitStruct.Pull = GPIO_PULLUP;
  GPIO_InitStruct.Speed = GPIO_SPEED_FREQ_LOW;
  HAL_GPIO_Init(GPIOE, &GPIO_InitStruct);

  /*Configure GPIO pin : EEPROM_SCL_Pin */
  GPIO_InitStruct.Pin = EEPROM_SCL_Pin;
  GPIO_InitStruct.Mode = GPIO_MODE_OUTPUT_PP;
  GPIO_InitStruct.Pull = GPIO_PULLUP;
  GPIO_InitStruct.Speed = GPIO_SPEED_FREQ_HIGH;
  HAL_GPIO_Init(EEPROM_SCL_GPIO_Port, &GPIO_InitStruct);

  /*Configure GPIO pin : EEPROM_SDA_Pin */
  GPIO_InitStruct.Pin = EEPROM_SDA_Pin;
  GPIO_InitStruct.Mode = GPIO_MODE_OUTPUT_OD;
  GPIO_InitStruct.Pull = GPIO_PULLUP;
  GPIO_InitStruct.Speed = GPIO_SPEED_FREQ_HIGH;
  HAL_GPIO_Init(EEPROM_SDA_GPIO_Port, &GPIO_InitStruct);

  /*Configure GPIO pins : MCU_USR2_nReset_Pin MCU_USR1_nReset_Pin */
  GPIO_InitStruct.Pin = MCU_USR2_nReset_Pin|MCU_USR1_nReset_Pin;
  GPIO_InitStruct.Mode = GPIO_MODE_OUTPUT_PP;
  GPIO_InitStruct.Pull = GPIO_PULLUP;
  GPIO_InitStruct.Speed = GPIO_SPEED_FREQ_LOW;
  HAL_GPIO_Init(GPIOD, &GPIO_InitStruct);

  /*Configure GPIO pin : LED1_Pin */
  GPIO_InitStruct.Pin = LED1_Pin;
  GPIO_InitStruct.Mode = GPIO_MODE_OUTPUT_PP;
  GPIO_InitStruct.Pull = GPIO_PULLUP;
  GPIO_InitStruct.Speed = GPIO_SPEED_FREQ_LOW;
  HAL_GPIO_Init(LED1_GPIO_Port, &GPIO_InitStruct);
  /* 使能电源指示灯 LED1 */
  HAL_GPIO_WritePin(LED1_GPIO_Port, LED1_Pin, GPIO_PIN_SET);

  /*Configure GPIO pins : LED2_Pin LED3_Pin LED4_Pin */
  GPIO_InitStruct.Pin = LED2_Pin|LED3_Pin|LED4_Pin;
  GPIO_InitStruct.Mode = GPIO_MODE_OUTPUT_PP;
  GPIO_InitStruct.Pull = GPIO_NOPULL;
  GPIO_InitStruct.Speed = GPIO_SPEED_FREQ_LOW;
  HAL_GPIO_Init(GPIOC, &GPIO_InitStruct);

  /*Configure GPIO pin : USR1_RTS_Pin */
  GPIO_InitStruct.Pin = USR1_RTS_Pin;
  GPIO_InitStruct.Mode = GPIO_MODE_OUTPUT_PP;
  GPIO_InitStruct.Pull = GPIO_PULLUP;
  GPIO_InitStruct.Speed = GPIO_SPEED_FREQ_LOW;
  HAL_GPIO_Init(USR1_RTS_GPIO_Port, &GPIO_InitStruct);

  /*Configure GPIO pin : USR1_CTS_Pin */
  GPIO_InitStruct.Pin = USR1_CTS_Pin;
  GPIO_InitStruct.Mode = GPIO_MODE_INPUT;
  GPIO_InitStruct.Pull = GPIO_PULLUP;
  HAL_GPIO_Init(USR1_CTS_GPIO_Port, &GPIO_InitStruct);

  /*Configure GPIO pin : MCU_USR1_nReload_Pin */
  GPIO_InitStruct.Pin = MCU_USR1_nReload_Pin;
  GPIO_InitStruct.Mode = GPIO_MODE_OUTPUT_PP;
  GPIO_InitStruct.Pull = GPIO_PULLUP;
  GPIO_InitStruct.Speed = GPIO_SPEED_FREQ_LOW;
  HAL_GPIO_Init(MCU_USR1_nReload_GPIO_Port, &GPIO_InitStruct);

  /* EXTI interrupt init*/
  HAL_NVIC_SetPriority(EXTI3_IRQn, 5, 0);
  HAL_NVIC_EnableIRQ(EXTI3_IRQn);

  HAL_NVIC_SetPriority(EXTI9_5_IRQn, 5, 0);
  HAL_NVIC_EnableIRQ(EXTI9_5_IRQn);

}

void StartCollectTask(void const * argument)
{
  /* USER CODE BEGIN 5 */

  /* Infinite loop */
    while (1) {
        osMutexWait( CommitMutexHandle, osWaitForever ); //加锁
        Collect_Handle(); //状态采集任务
        Collect_UploadHandle();//数据上报处理
        WIFI_Uart_Handle();//处理WIFI数据
        osMutexRelease( CommitMutexHandle );
        osDelay(50);
    }
  /* USER CODE END 5 */
}

void StartConfigTask(void const * argument)
{
  /* USER CODE BEGIN StartConfigTask */
  /* Infinite loop */
    while (1) {
        osMutexWait( CommitMutexHandle, osWaitForever );//加锁
        Config_Uart_Handle();
        Config_UploadMonitorState();
        osMutexRelease( CommitMutexHandle );
        osDelay(50);
    }
  /* USER CODE END StartConfigTask */
}

void StartOutControlTask(void const * argument)
{
  /* USER CODE BEGIN StartOutControlTask */
  /* Infinite loop */
    while (1) {
        Outcontrol_Handle();
        osDelay(50);
    }
  /* USER CODE END StartOutControlTask */
}

void StartCollectTask_new(void const * argument)
{
  EpCnt epcnt;
  for(;;)
  {
    g_sys_sts.col_sts.mainpulsecount =
			collect_get_paper_cnt();
	g_sys_sts.col_sts.revpulsecount =
			collect_get_qt_cnt();
	epcnt = collect_get_ep_cnt();
	g_sys_sts.col_sts.bladepulsecount =
			epcnt.epcnt;
	g_sys_sts.col_sts.bladepulsetime =
			epcnt.eptime;
    osDelay(50);
  }
}

void HAL_TIM_PeriodElapsedCallback(TIM_HandleTypeDef *htim)
{
  if (htim->Instance == TIM14) {
    HAL_IncTick();
  }
  /* USER CODE BEGIN Callback 1 */
   TIM_PeriodElapsedCallback(htim);
  /* USER CODE END Callback 1 */
}

void Error_Handler(void)
{
}

/************************ (C) COPYRIGHT STMicroelectronics *****END OF FILE****/
